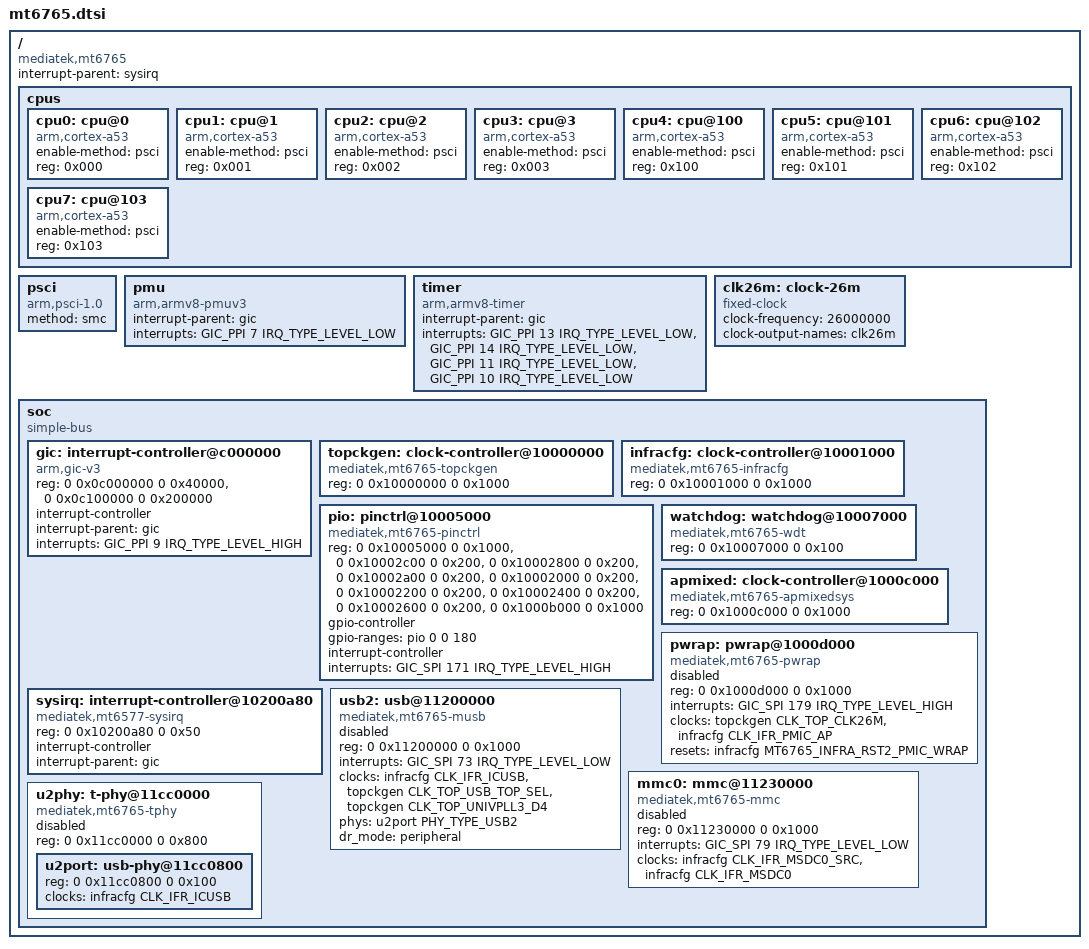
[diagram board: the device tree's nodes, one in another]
// SPDX-License-Identifier: (GPL-2.0 OR MIT)
/* MediaTek MT6765/MT8768 SoC */

#include <dt-bindings/clock/mt6765-clk.h>
#include <dt-bindings/interrupt-controller/arm-gic.h>
#include <dt-bindings/interrupt-controller/irq.h>
#include <dt-bindings/phy/phy.h>
#include <dt-bindings/pinctrl/mt65xx.h>
#include <dt-bindings/reset/mediatek,mt6765-infracfg.h>

/ {
	compatible = "mediatek,mt6765";
	interrupt-parent = <&sysirq>;
	#address-cells = <2>;
	#size-cells = <2>;

	cpus {
		#address-cells = <1>;
		#size-cells = <0>;

		cpu0: cpu@0 {
			compatible = "arm,cortex-a53";
			device_type = "cpu";
			enable-method = "psci";
			reg = <0x000>;
		};

		cpu1: cpu@1 {
			compatible = "arm,cortex-a53";
			device_type = "cpu";
			enable-method = "psci";
			reg = <0x001>;
		};

		cpu2: cpu@2 {
			compatible = "arm,cortex-a53";
			device_type = "cpu";
			enable-method = "psci";
			reg = <0x002>;
		};

		cpu3: cpu@3 {
			compatible = "arm,cortex-a53";
			device_type = "cpu";
			enable-method = "psci";
			reg = <0x003>;
		};

		cpu4: cpu@100 {
			compatible = "arm,cortex-a53";
			device_type = "cpu";
			enable-method = "psci";
			reg = <0x100>;
		};

		cpu5: cpu@101 {
			compatible = "arm,cortex-a53";
			device_type = "cpu";
			enable-method = "psci";
			reg = <0x101>;
		};

		cpu6: cpu@102 {
			compatible = "arm,cortex-a53";
			device_type = "cpu";
			enable-method = "psci";
			reg = <0x102>;
		};

		cpu7: cpu@103 {
			compatible = "arm,cortex-a53";
			device_type = "cpu";
			enable-method = "psci";
			reg = <0x103>;
		};
	};

	psci {
		compatible = "arm,psci-1.0";
		method = "smc";
	};

	pmu {
		compatible = "arm,armv8-pmuv3";
		interrupt-parent = <&gic>;
		interrupts = <GIC_PPI 7 IRQ_TYPE_LEVEL_LOW>;
	};

	timer {
		compatible = "arm,armv8-timer";
		interrupt-parent = <&gic>;
		interrupts = <GIC_PPI 13 IRQ_TYPE_LEVEL_LOW>,
			     <GIC_PPI 14 IRQ_TYPE_LEVEL_LOW>,
			     <GIC_PPI 11 IRQ_TYPE_LEVEL_LOW>,
			     <GIC_PPI 10 IRQ_TYPE_LEVEL_LOW>;
	};

	clk26m: clock-26m {
		compatible = "fixed-clock";
		#clock-cells = <0>;
		clock-frequency = <26000000>;
		clock-output-names = "clk26m";
	};

	soc {
		compatible = "simple-bus";
		#address-cells = <2>;
		#size-cells = <2>;
		ranges;

		gic: interrupt-controller@c000000 {
			compatible = "arm,gic-v3";
			reg = <0 0x0c000000 0 0x40000>,
			      <0 0x0c100000 0 0x200000>;
			interrupt-controller;
			#interrupt-cells = <3>;
			interrupt-parent = <&gic>;
			interrupts = <GIC_PPI 9 IRQ_TYPE_LEVEL_HIGH>;
		};

		topckgen: clock-controller@10000000 {
			compatible = "mediatek,mt6765-topckgen", "syscon";
			reg = <0 0x10000000 0 0x1000>;
			#clock-cells = <1>;
		};

		infracfg: clock-controller@10001000 {
			compatible = "mediatek,mt6765-infracfg", "syscon";
			reg = <0 0x10001000 0 0x1000>;
			#clock-cells = <1>;
			#reset-cells = <1>;
		};

		pio: pinctrl@10005000 {
			compatible = "mediatek,mt6765-pinctrl";
			reg = <0 0x10005000 0 0x1000>,
			      <0 0x10002c00 0 0x200>,
			      <0 0x10002800 0 0x200>,
			      <0 0x10002a00 0 0x200>,
			      <0 0x10002000 0 0x200>,
			      <0 0x10002200 0 0x200>,
			      <0 0x10002400 0 0x200>,
			      <0 0x10002600 0 0x200>,
			      <0 0x1000b000 0 0x1000>;
			reg-names = "iocfg0", "iocfg1", "iocfg2", "iocfg3",
				    "iocfg4", "iocfg5", "iocfg6", "iocfg7",
				    "eint";
			gpio-controller;
			#gpio-cells = <2>;
			gpio-ranges = <&pio 0 0 180>;
			interrupt-controller;
			#interrupt-cells = <2>;
			interrupts = <GIC_SPI 171 IRQ_TYPE_LEVEL_HIGH>;
		};

		watchdog: watchdog@10007000 {
			compatible = "mediatek,mt6765-wdt",
				     "mediatek,mt6589-wdt";
			reg = <0 0x10007000 0 0x100>;
		};

		apmixed: clock-controller@1000c000 {
			compatible = "mediatek,mt6765-apmixedsys", "syscon";
			reg = <0 0x1000c000 0 0x1000>;
			#clock-cells = <1>;
		};

		pwrap: pwrap@1000d000 {
			compatible = "mediatek,mt6765-pwrap";
			reg = <0 0x1000d000 0 0x1000>;
			reg-names = "pwrap";
			interrupts = <GIC_SPI 179 IRQ_TYPE_LEVEL_HIGH>;
			clocks = <&topckgen CLK_TOP_CLK26M>,
				 <&infracfg CLK_IFR_PMIC_AP>;
			clock-names = "spi", "wrap";
			resets = <&infracfg MT6765_INFRA_RST2_PMIC_WRAP>;
			reset-names = "pwrap";
			status = "disabled";
		};

		sysirq: interrupt-controller@10200a80 {
			compatible = "mediatek,mt6577-sysirq";
			reg = <0 0x10200a80 0 0x50>;
			interrupt-controller;
			#interrupt-cells = <3>;
			interrupt-parent = <&gic>;
		};

		usb2: usb@11200000 {
			compatible = "mediatek,mt6765-musb", "mediatek,mtk-musb";
			reg = <0 0x11200000 0 0x1000>;
			interrupts = <GIC_SPI 73 IRQ_TYPE_LEVEL_LOW>;
			interrupt-names = "mc";
			clocks = <&infracfg CLK_IFR_ICUSB>,
				 <&topckgen CLK_TOP_USB_TOP_SEL>,
				 <&topckgen CLK_TOP_UNIVPLL3_D4>;
			clock-names = "main", "mcu", "univpll";
			phys = <&u2port PHY_TYPE_USB2>;
			dr_mode = "peripheral";
			status = "disabled";
		};

		mmc0: mmc@11230000 {
			compatible = "mediatek,mt6765-mmc";
			reg = <0 0x11230000 0 0x1000>;
			interrupts = <GIC_SPI 79 IRQ_TYPE_LEVEL_LOW>;
			clocks = <&infracfg CLK_IFR_MSDC0_SRC>,
				 <&infracfg CLK_IFR_MSDC0>;
			clock-names = "source", "hclk";
			status = "disabled";
		};

		u2phy: t-phy@11cc0000 {
			compatible = "mediatek,mt6765-tphy", "mediatek,generic-tphy-v1";
			reg = <0 0x11cc0000 0 0x800>;
			#address-cells = <2>;
			#size-cells = <2>;
			ranges;
			status = "disabled";

			u2port: usb-phy@11cc0800 {
				reg = <0 0x11cc0800 0 0x100>;
				clocks = <&infracfg CLK_IFR_ICUSB>;
				clock-names = "ref";
				#phy-cells = <1>;
			};
		};
	};
};
